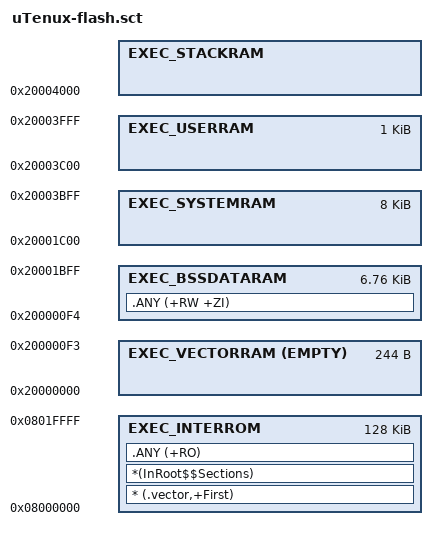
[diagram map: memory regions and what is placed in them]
;*
;*----------------------------------------------------------------------------------------
;*    IDE
;*
;*    Copyright (C) 2008-2017 by Dalian uLoong Co.,Ltd. All rights reserved.
;*    
;*    This program is open source software; developer can redistribute it and/or
;*    modify it under the terms of the U-License as published by the Tenux Open Source
;*    Society; either version 1 of the License, or (at developer option) any later 
;*    Version.
;*    
;*    This program is distributed in the hope that it will be useful,but WITHOUT ANY 
;*    WARRANTY; without even the implied warranty of MERCHANTABILITY or FITNESS FOR 
;*    A PARTICULAR PURPOSE.  See the U-License for more details.
;*    
;*    Developer should have received a copy of the U-License along with this program;
;*    if not, download from www.tenux.org(the web page of the Tenux Open Source Society).
;*
;*    CPU:        STM32L152RB Compiled by KEIL RVMDK
;*    RTOS:       uT/OS
;*    Version:    2.0.00
;*    Released by Tenux Open Source Society
;*                  (http://www.tenux.org).
;*
;*    File Name      : uTenux-flash.sct
;*    Create Date    : 2013/9/23-2017/11/07
;*    Author         : Zhangzl-Cuihl/Wangshb
;*    Description    : flash Linker Scatter-Loading Description File .
;*----------------------------------------------------------------------------------------
;*/

LOAD_INTERFLASHROM 0x08000000       0x00020000 { ; load region size_region
  EXEC_INTERROM    0x08000000       0x00020000 { ; load address = execution address
   * (.vector,+First)                            ;                            128k
   *(InRoot$$Sections)
   .ANY (+RO)
  }
  EXEC_VECTORRAM   0x20000000 EMPTY 0x000000f4 { ; vector table region in ram 
  }                                              ;                            0.2k
  EXEC_BSSDATARAM  0x200000f4       0x00001b0c { ; zi and rw data region in ram 
   .ANY (+RW +ZI) 
  }                                              ;                            6.8k
  EXEC_SYSTEMRAM   0x20001c00       0x00002000 { ; ut/kernel management region 
  }                                              ;                              8k
  EXEC_USERRAM     0x20003c00       0x00000400 { ; user manual region in ram 
  }                                              ;                              1k
  EXEC_STACKRAM    0x20004000       0x00000000 { ; default stack top
  }                                              ;                              0k
}                                                ;                       sum:  16k

